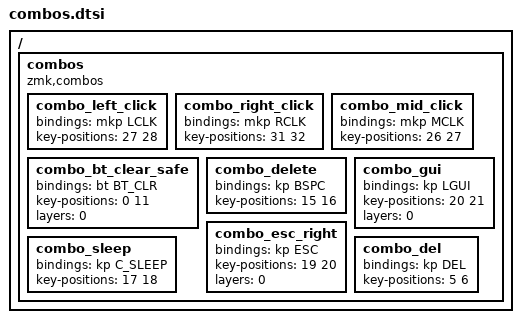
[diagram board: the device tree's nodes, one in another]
/ {
    combos {
        compatible = "zmk,combos";
      
        combo_left_click {
            bindings = <&mkp LCLK>;
            key-positions = <27 28>;
        };

        combo_right_click {
            bindings = <&mkp RCLK>;
            key-positions = <31 32>;
        };

        combo_mid_click {
            bindings = <&mkp MCLK>;
            key-positions = <26 27>;
        };

        combo_bt_clear_safe {
            bindings = <&bt BT_CLR>;
            key-positions = <0 11>;
            layers = <0>;
        };

        combo_delete {
            bindings = <&kp BSPC>;
            key-positions = <15 16>;
        };

        combo_gui {
            bindings = <&kp LGUI>;
            key-positions = <20 21>;
            layers = <0>;
        };

        combo_esc_right {
            bindings = <&kp ESC>;
            key-positions = <19 20>;
            layers = <0>;
        };

        combo_sleep {
            bindings = <&kp C_SLEEP>;
            key-positions = <17 18>;
        };

        combo_del {
            bindings = <&kp DEL>;
            key-positions = <5 6>;
        };

    };
};
